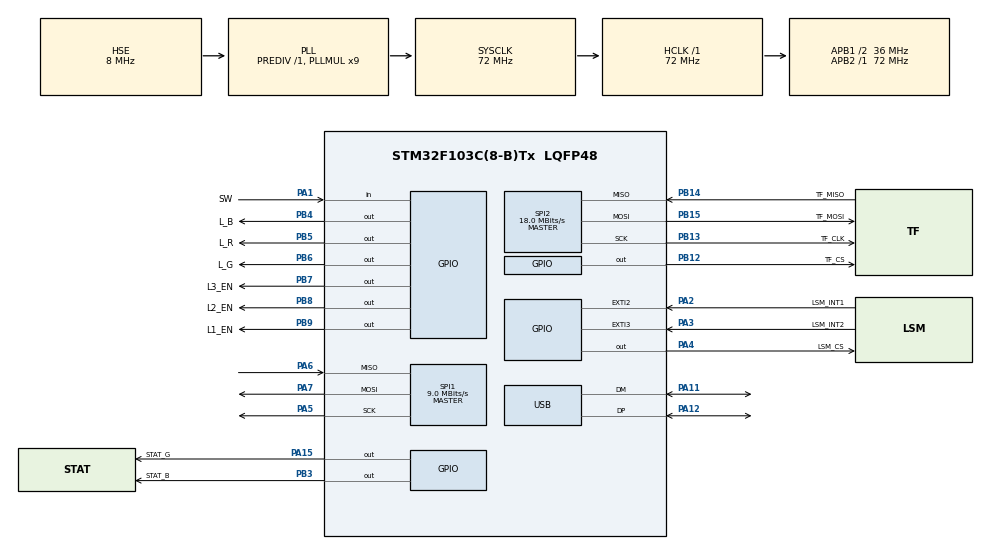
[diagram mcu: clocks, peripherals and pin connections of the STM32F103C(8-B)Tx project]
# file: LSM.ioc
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FATFS._MAX_SS=4096
FATFS._USE_LFN=1
Mcu.Family=STM32F1
Mcu.Name=STM32F103C(8-B)Tx
Mcu.Package=LQFP48
NVIC.PriorityGroup=NVIC_PRIORITYGROUP_4
NVIC.USB_LP_CAN1_RX0_IRQn=true\:0\:0\:false\:false\:true\:false\:true
PA1.GPIO_Label=SW
PA1.GPIO_PuPd=GPIO_PULLUP
PA1.Signal=GPIO_Input
PA11.Mode=Device
PA11.Signal=USB_DM
PA12.Mode=Device
PA12.Signal=USB_DP
PA13.Mode=Serial_Wire
PA13.Signal=SYS_JTMS-SWDIO
PA14.Mode=Serial_Wire
PA14.Signal=SYS_JTCK-SWCLK
PA15.GPIO_Label=STAT_G
PA15.PinState=GPIO_PIN_SET
PA15.Signal=GPIO_Output
PA2.GPIO_Label=LSM_INT1
PA2.Signal=GPXTI2
PA3.GPIO_Label=LSM_INT2
PA3.Signal=GPXTI3
PA4.GPIO_Label=LSM_CS
PA4.PinState=GPIO_PIN_SET
PA4.Signal=GPIO_Output
PA5.Mode=Full_Duplex_Master
PA5.Signal=SPI1_SCK
PA6.Mode=Full_Duplex_Master
PA6.Signal=SPI1_MISO
PA7.Mode=Full_Duplex_Master
PA7.Signal=SPI1_MOSI
PB12.GPIO_Label=TF_CS
PB12.PinState=GPIO_PIN_SET
PB12.Signal=GPIO_Output
PB13.GPIO_Label=TF_CLK
PB13.Mode=Full_Duplex_Master
PB13.Signal=SPI2_SCK
PB14.GPIO_Label=TF_MISO
PB14.Mode=Full_Duplex_Master
PB14.Signal=SPI2_MISO
PB15.GPIO_Label=TF_MOSI
PB15.Mode=Full_Duplex_Master
PB15.Signal=SPI2_MOSI
PB3.GPIO_Label=STAT_B
PB3.PinState=GPIO_PIN_SET
PB3.Signal=GPIO_Output
PB4.GPIO_Label=L_B
PB4.GPIO_ModeDefaultOutputPP=GPIO_MODE_OUTPUT_OD
PB4.GPIO_Speed=GPIO_SPEED_FREQ_HIGH
PB4.PinState=GPIO_PIN_SET
PB4.Signal=GPIO_Output
PB5.GPIO_Label=L_R
PB5.GPIO_ModeDefaultOutputPP=GPIO_MODE_OUTPUT_OD
PB5.GPIO_Speed=GPIO_SPEED_FREQ_HIGH
PB5.PinState=GPIO_PIN_SET
PB5.Signal=GPIO_Output
PB6.GPIO_Label=L_G
PB6.GPIO_ModeDefaultOutputPP=GPIO_MODE_OUTPUT_OD
PB6.GPIO_Speed=GPIO_SPEED_FREQ_HIGH
PB6.PinState=GPIO_PIN_SET
PB6.Signal=GPIO_Output
PB7.GPIO_Label=L3_EN
PB7.GPIO_Speed=GPIO_SPEED_FREQ_HIGH
PB7.Signal=GPIO_Output
PB8.GPIO_Label=L2_EN
PB8.GPIO_Speed=GPIO_SPEED_FREQ_HIGH
PB8.Signal=GPIO_Output
PB9.GPIO_Label=L1_EN
PB9.GPIO_Speed=GPIO_SPEED_FREQ_HIGH
PB9.Signal=GPIO_Output
PD0-OSC_IN.Mode=HSE-External-Oscillator
PD0-OSC_IN.Signal=RCC_OSC_IN
PD1-OSC_OUT.Mode=HSE-External-Oscillator
PD1-OSC_OUT.Signal=RCC_OSC_OUT
ProjectManager.HeapSize=0x400
ProjectManager.StackSize=0x400
ProjectManager.TargetToolchain=MDK-ARM V5.27
RCC.AHBFreq_Value=72000000
RCC.APB1CLKDivider=RCC_HCLK_DIV2
RCC.APB1Freq_Value=36000000
RCC.APB1TimFreq_Value=72000000
RCC.APB2Freq_Value=72000000
RCC.APB2TimFreq_Value=72000000
RCC.HCLKFreq_Value=72000000
RCC.PLLMUL=RCC_PLL_MUL9
RCC.SYSCLKFreq_VALUE=72000000
RCC.SYSCLKSource=RCC_SYSCLKSOURCE_PLLCLK
RCC.USBFreq_Value=48000000
RCC.USBPrescaler=RCC_USBCLKSOURCE_PLL_DIV1_5
SPI1.BaudRatePrescaler=SPI_BAUDRATEPRESCALER_8
SPI1.CLKPhase=SPI_PHASE_2EDGE
SPI1.CLKPolarity=SPI_POLARITY_HIGH
SPI1.CalculateBaudRate=9.0 MBits/s
SPI1.Direction=SPI_DIRECTION_2LINES
SPI1.Mode=SPI_MODE_MASTER
SPI1.VirtualType=VM_MASTER
SPI2.BaudRatePrescaler=SPI_BAUDRATEPRESCALER_2
SPI2.CalculateBaudRate=18.0 MBits/s
SPI2.Direction=SPI_DIRECTION_2LINES
SPI2.Mode=SPI_MODE_MASTER
SPI2.VirtualType=VM_MASTER
USB.low_power_enable=DISABLE
USB.lpm_enable=DISABLE
USB_DEVICE.CLASS_NAME_FS=CDC
USB_DEVICE.USBD_DEBUG_LEVEL=0
USB_DEVICE.VirtualMode=Cdc
USB_DEVICE.VirtualModeFS=Cdc_FS
VP_FATFS_VS_Generic.Mode=User_defined
VP_USB_DEVICE_VS_USB_DEVICE_CDC_FS.Mode=CDC_FS
board=custom

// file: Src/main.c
/* USER CODE BEGIN Header */
/**
  ******************************************************************************
  * @file           : main.c
  * @brief          : Main program body
  ******************************************************************************
  * @attention
  *
  * <h2><center>&copy; Copyright (c) 2020 STMicroelectronics.
  * All rights reserved.</center></h2>
  *
  * This software component is licensed by ST under Ultimate Liberty license
  * SLA0044, the "License"; You may not use this file except in compliance with
  * the License. You may obtain a copy of the License at:
  *                             www.st.com/SLA0044
  *
  ******************************************************************************
  */
/* USER CODE END Header */

#include "main.h"
#include "fatfs.h"
#include "usb_device.h"

/* USER CODE BEGIN Includes */
#include "app.h"
/* USER CODE END Includes */

/* USER CODE BEGIN PD */
#define  USE_FULL_ASSERT 1

/* USER CODE END PD */

SPI_HandleTypeDef hspi1;
SPI_HandleTypeDef hspi2;

void SystemClock_Config(void);
static void MX_GPIO_Init(void);
static void MX_SPI2_Init(void);
static void MX_SPI1_Init(void);

int main(void)
{

  /* MCU Configuration--------------------------------------------------------*/

  /* Reset of all peripherals, Initializes the Flash interface and the Systick. */
  HAL_Init();

  /* Configure the system clock */
  SystemClock_Config();

  /* Initialize all configured peripherals */
  MX_GPIO_Init();
  MX_SPI2_Init();
  MX_USB_DEVICE_Init();
  MX_SPI1_Init();
  MX_FATFS_Init();
  /* USER CODE BEGIN 2 */
    BSP_Init();
  /* USER CODE END 2 */

  /* Infinite loop */
  /* USER CODE BEGIN WHILE */
  while (1)
  {

    APP_loop();
    HAL_Delay(4);
    /* USER CODE END WHILE */

  }
}

void SystemClock_Config(void)
{
  RCC_OscInitTypeDef RCC_OscInitStruct = {0};
  RCC_ClkInitTypeDef RCC_ClkInitStruct = {0};
  RCC_PeriphCLKInitTypeDef PeriphClkInit = {0};

  /** Initializes the CPU, AHB and APB busses clocks
  */
  RCC_OscInitStruct.OscillatorType = RCC_OSCILLATORTYPE_HSE;
  RCC_OscInitStruct.HSEState = RCC_HSE_ON;
  RCC_OscInitStruct.HSEPredivValue = RCC_HSE_PREDIV_DIV1;
  RCC_OscInitStruct.HSIState = RCC_HSI_ON;
  RCC_OscInitStruct.PLL.PLLState = RCC_PLL_ON;
  RCC_OscInitStruct.PLL.PLLSource = RCC_PLLSOURCE_HSE;
  RCC_OscInitStruct.PLL.PLLMUL = RCC_PLL_MUL9;
  if (HAL_RCC_OscConfig(&RCC_OscInitStruct) != HAL_OK)
  {
    Error_Handler();
  }
  /** Initializes the CPU, AHB and APB busses clocks
  */
  RCC_ClkInitStruct.ClockType = RCC_CLOCKTYPE_HCLK|RCC_CLOCKTYPE_SYSCLK
                              |RCC_CLOCKTYPE_PCLK1|RCC_CLOCKTYPE_PCLK2;
  RCC_ClkInitStruct.SYSCLKSource = RCC_SYSCLKSOURCE_PLLCLK;
  RCC_ClkInitStruct.AHBCLKDivider = RCC_SYSCLK_DIV1;
  RCC_ClkInitStruct.APB1CLKDivider = RCC_HCLK_DIV2;
  RCC_ClkInitStruct.APB2CLKDivider = RCC_HCLK_DIV1;

  if (HAL_RCC_ClockConfig(&RCC_ClkInitStruct, FLASH_LATENCY_2) != HAL_OK)
  {
    Error_Handler();
  }
  PeriphClkInit.PeriphClockSelection = RCC_PERIPHCLK_USB;
  PeriphClkInit.UsbClockSelection = RCC_USBCLKSOURCE_PLL_DIV1_5;
  if (HAL_RCCEx_PeriphCLKConfig(&PeriphClkInit) != HAL_OK)
  {
    Error_Handler();
  }
}

static void MX_SPI1_Init(void)
{

  /* SPI1 parameter configuration*/
  hspi1.Instance = SPI1;
  hspi1.Init.Mode = SPI_MODE_MASTER;
  hspi1.Init.Direction = SPI_DIRECTION_2LINES;
  hspi1.Init.DataSize = SPI_DATASIZE_8BIT;
  hspi1.Init.CLKPolarity = SPI_POLARITY_HIGH;
  hspi1.Init.CLKPhase = SPI_PHASE_2EDGE;
  hspi1.Init.NSS = SPI_NSS_SOFT;
  hspi1.Init.BaudRatePrescaler = SPI_BAUDRATEPRESCALER_8;
  hspi1.Init.FirstBit = SPI_FIRSTBIT_MSB;
  hspi1.Init.TIMode = SPI_TIMODE_DISABLE;
  hspi1.Init.CRCCalculation = SPI_CRCCALCULATION_DISABLE;
  hspi1.Init.CRCPolynomial = 10;
  if (HAL_SPI_Init(&hspi1) != HAL_OK)
  {
    Error_Handler();
  }

}

static void MX_SPI2_Init(void)
{

  /* SPI2 parameter configuration*/
  hspi2.Instance = SPI2;
  hspi2.Init.Mode = SPI_MODE_MASTER;
  hspi2.Init.Direction = SPI_DIRECTION_2LINES;
  hspi2.Init.DataSize = SPI_DATASIZE_8BIT;
  hspi2.Init.CLKPolarity = SPI_POLARITY_LOW;
  hspi2.Init.CLKPhase = SPI_PHASE_1EDGE;
  hspi2.Init.NSS = SPI_NSS_SOFT;
  hspi2.Init.BaudRatePrescaler = SPI_BAUDRATEPRESCALER_2;
  hspi2.Init.FirstBit = SPI_FIRSTBIT_MSB;
  hspi2.Init.TIMode = SPI_TIMODE_DISABLE;
  hspi2.Init.CRCCalculation = SPI_CRCCALCULATION_DISABLE;
  hspi2.Init.CRCPolynomial = 10;
  if (HAL_SPI_Init(&hspi2) != HAL_OK)
  {
    Error_Handler();
  }

}

static void MX_GPIO_Init(void)
{
  GPIO_InitTypeDef GPIO_InitStruct = {0};

  /* GPIO Ports Clock Enable */
  __HAL_RCC_GPIOD_CLK_ENABLE();
  __HAL_RCC_GPIOA_CLK_ENABLE();
  __HAL_RCC_GPIOB_CLK_ENABLE();

  /*Configure GPIO pin Output Level */
  HAL_GPIO_WritePin(GPIOA, LSM_CS_Pin|STAT_G_Pin, GPIO_PIN_SET);

  /*Configure GPIO pin Output Level */
  HAL_GPIO_WritePin(GPIOB, TF_CS_Pin|STAT_B_Pin|L_B_Pin|L_R_Pin
                          |L_G_Pin, GPIO_PIN_SET);

  /*Configure GPIO pin Output Level */
  HAL_GPIO_WritePin(GPIOB, L3_EN_Pin|L2_EN_Pin|L1_EN_Pin, GPIO_PIN_RESET);

  /*Configure GPIO pin : SW_Pin */
  GPIO_InitStruct.Pin = SW_Pin;
  GPIO_InitStruct.Mode = GPIO_MODE_INPUT;
  GPIO_InitStruct.Pull = GPIO_PULLUP;
  HAL_GPIO_Init(SW_GPIO_Port, &GPIO_InitStruct);

  /*Configure GPIO pins : LSM_INT1_Pin LSM_INT2_Pin */
  GPIO_InitStruct.Pin = LSM_INT1_Pin|LSM_INT2_Pin;
  GPIO_InitStruct.Mode = GPIO_MODE_IT_RISING;
  GPIO_InitStruct.Pull = GPIO_NOPULL;
  HAL_GPIO_Init(GPIOA, &GPIO_InitStruct);

  /*Configure GPIO pins : LSM_CS_Pin STAT_G_Pin */
  GPIO_InitStruct.Pin = LSM_CS_Pin|STAT_G_Pin;
  GPIO_InitStruct.Mode = GPIO_MODE_OUTPUT_PP;
  GPIO_InitStruct.Pull = GPIO_NOPULL;
  GPIO_InitStruct.Speed = GPIO_SPEED_FREQ_LOW;
  HAL_GPIO_Init(GPIOA, &GPIO_InitStruct);

  /*Configure GPIO pins : TF_CS_Pin STAT_B_Pin */
  GPIO_InitStruct.Pin = TF_CS_Pin|STAT_B_Pin;
  GPIO_InitStruct.Mode = GPIO_MODE_OUTPUT_PP;
  GPIO_InitStruct.Pull = GPIO_NOPULL;
  GPIO_InitStruct.Speed = GPIO_SPEED_FREQ_LOW;
  HAL_GPIO_Init(GPIOB, &GPIO_InitStruct);

  /*Configure GPIO pins : L_B_Pin L_R_Pin L_G_Pin */
  GPIO_InitStruct.Pin = L_B_Pin|L_R_Pin|L_G_Pin;
  GPIO_InitStruct.Mode = GPIO_MODE_OUTPUT_OD;
  GPIO_InitStruct.Pull = GPIO_NOPULL;
  GPIO_InitStruct.Speed = GPIO_SPEED_FREQ_HIGH;
  HAL_GPIO_Init(GPIOB, &GPIO_InitStruct);

  /*Configure GPIO pins : L3_EN_Pin L2_EN_Pin L1_EN_Pin */
  GPIO_InitStruct.Pin = L3_EN_Pin|L2_EN_Pin|L1_EN_Pin;
  GPIO_InitStruct.Mode = GPIO_MODE_OUTPUT_PP;
  GPIO_InitStruct.Pull = GPIO_NOPULL;
  GPIO_InitStruct.Speed = GPIO_SPEED_FREQ_HIGH;
  HAL_GPIO_Init(GPIOB, &GPIO_InitStruct);

}

void Error_Handler(void)
{
}

#ifdef  USE_FULL_ASSERT
/**
  * @brief  Reports the name of the source file and the source line number
  *         where the assert_param error has occurred.
  * @param  file: pointer to the source file name
  * @param  line: assert_param error line source number
  * @retval None
  */
void assert_failed(uint8_t *file, uint32_t line)
{
  /* USER CODE BEGIN 6 */
  /* User can add his own implementation to report the file name and line number, */
    usb_printf("Wrong parameters value: file %s on line %d\r\n", file, line);
    while(1);
  /* USER CODE END 6 */
}
#endif /* USE_FULL_ASSERT */

/************************ (C) COPYRIGHT STMicroelectronics *****END OF FILE****/
